# MINI58DE_v1 register map
File version: 1.0
Registers are 32-bit, read-write, reset 0x0 unless marked. A register's access mark holds for its fields unless they carry their own. Offsets are from the block's base; [hi:lo] are bit positions; {n}, {i} and the like mark numbered series.

## INT — INT Register Map
Base 0x50000300
0x00 IRQ0_SRC ro reset not defined — IRQ0 (BOD) Interrupt Source Identity
  [0] BOD_INT — IRQ0 Source Identity
    0=IRQ0 source is not from BOD interrupt (BOD_INT); 1=IRQ0 source is from BOD interrupt (BOD_INT)
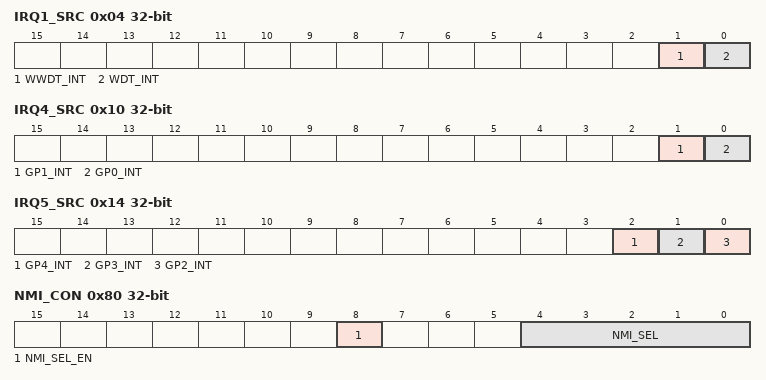
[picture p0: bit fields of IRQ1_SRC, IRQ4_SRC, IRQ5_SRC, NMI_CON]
0x04 IRQ1_SRC ro reset not defined — IRQ1 (WDT) Interrupt Source Identity
  [1] WWDT_INT — IRQ1 Source Identity
    0=IRQ1 source is not from window watchdog interrupt (WWDT _INT); 1=IRQ1 source is from window watchdog interrupt (WWDT_INT)
  [0] WDT_INT — IRQ1 Source Identity
    0=IRQ1 source is not from watchdog interrupt (WDT _INT); 1=IRQ1 source is from watchdog interrupt (WDT_INT)
0x08 IRQ2_SRC ro reset not defined — IRQ2 (EINT0) Interrupt Source Identity
  [0] EINT0 — IRQ2 Source Identity
    0=IRQ2 source is not from external signal interrupt 0 from P3.2 (EINT0); 1=IRQ2 source is from external signal interrupt 0 from P3.2 (EINT0)
0x0C IRQ3_SRC ro reset not defined — IRQ3 (EINT1) Interrupt Source Identity
  [0] EINT1 — IRQ3 Source Identity
    0=IRQ3 source is not from external signal interrupt 1 from P5.2 (EINT1); 1=IRQ3 source is from external signal interrupt 1 from P5.2 (EINT1)
0x10 IRQ4_SRC ro reset not defined — IRQ4 (GP0/1) Interrupt Source Identity
  [1] GP1_INT — IRQ4 Source Identity
    0=IRQ4 source is not from GP1 interrupt (GP1_INT); 1=IRQ4 source is from GP1 interrupt (GP1_INT)
  [0] GP0_INT — IRQ4 Source Identity
    0=IRQ4 source is not from GP0 interrupt (GP0_INT); 1=IRQ4 source is from GP0 interrupt (GP0_INT)
0x14 IRQ5_SRC ro reset not defined — IRQ5 (GP2/3/4) Interrupt Source Identity
  [2] GP4_INT — IRQ5 Source Identity
    0=IRQ5 source is not from GP4 interrupt (GP4_INT); 1=IRQ5 source is from GP4 interrupt (GP4_INT)
  [1] GP3_INT — IRQ5 Source Identity
    0=IRQ5 source is not from GP3 interrupt (GP3_INT); 1=IRQ5 source is from GP3 interrupt (GP3_INT)
  [0] GP2_INT — IRQ5 Source Identity
    0=IRQ5 source is not from GP2 interrupt (GP2_INT); 1=IRQ5 source is from GP2 interrupt (GP2_INT)
0x18 IRQ6_SRC ro reset not defined — IRQ6 (PWM) Interrupt Source Identity
  [0] PWM_INT — IRQ6 Source Identity
    0=IRQ6 source is not from PWM interrupt (PWM_INT); 1=IRQ6 source is from PWM interrupt (PWM_INT)
0x1C IRQ7_SRC ro reset not defined — IRQ7 (BRAKE) Interrupt Source Identity
  [0] BRAKE_INT — IRQ7 Source Identity
    0=IRQ7 source is not from Brake interrupt (BRAKE_INT); 1=IRQ7 source is from Brake interrupt (BRAKE_INT)
0x20 IRQ8_SRC ro reset not defined — IRQ8 (TMR0) Interrupt Source Identity
  [0] TMR0_INT — IRQ8 Source Identity
    0=IRQ8 source is not from Timer0 interrupt (TMR0_INT); 1=IRQ8 source is from Timer0 interrupt (TMR0_INT)
0x24 IRQ9_SRC ro reset not defined — IRQ9 (TMR1) Interrupt Source Identity
  [0] TMR1_INT — IRQ9 Source Identity
    0=IRQ9 source is not from Timer1 interrupt (TMR1_INT); 1=IRQ9 source is from Timer1 interrupt (TMR1_INT)
0x28 IRQ10_SRC reset not defined — Reserved
0x2C IRQ11_SRC reset not defined — Reserved
0x30 IRQ12_SRC ro reset not defined — IRQ12 (UART0) Interrupt Source Identity
  [0] UART0_INT — IRQ12 Source Identity
    0=IRQ12 source is not from UART0 interrupt (UART0_INT); 1=IRQ12 source is from UART0 interrupt (UART0_INT)
0x34 IRQ13_SRC ro reset not defined — IRQ13 (UART1) Interrupt Source Identity
  [0] UART1_INT — IRQ13 Source Identity
    0=IRQ13 source is not from UART1 interrupt (UART1_INT); 1=IRQ13 source is from UART1 interrupt (UART1_INT)
0x38 IRQ14_SRC ro reset not defined — IRQ14 (SPI) Interrupt Source Identity
  [0] SPI_INT — IRQ14 Source Identity
    0=IRQ14 source is not from SPI interrupt (SPI_INT); 1=IRQ14 source is from SPI interrupt (SPI_INT)
0x3C IRQ15_SRC reset not defined — Reserved
0x40 IRQ16_SRC ro reset not defined — IRQ16 (GP5) Interrupt Source Identity
  [0] GP5_INT — IRQ16 Source Identity
    0=IRQ16 source is not from GP5 interrupt (GP5_INT); 1=IRQ16 source is from GP5 interrupt (GP5_INT)
0x44 IRQ17_SRC ro reset not defined — IRQ17 (HIRC Trim) Interrupt Source Identity
  [0] HIRC_TRIM_INT — IRQ17 Source Identity
    0=IRQ17 source is not from HIRC trim interrupt (HIRC_TRIM_INT); 1=IRQ17 source is from HIRC trim interrupt (HIRC_TRIM_INT)
0x48 IRQ18_SRC ro reset not defined — IRQ18 (I2C0) Interrupt Source Identity
  [0] I2C0_INT — IRQ18 Source Identity
    0=IRQ18 source is not from I2C0 interrupt (I2C0_INT); 1=IRQ18 source is from I2C0 interrupt (I2C0_INT)
0x4C IRQ19_SRC ro reset not defined — IRQ19 (I2C1) Interrupt Source Identity
  [0] I2C1_INT — IRQ19 Source Identity
    0=IRQ19 source is not from I2C1 interrupt (I2C1_INT); 1=IRQ19 source is from I2C1 interrupt (I2C1_INT)
{0x0+4i} IRQ{i}_SRC reset not defined (i=20..24) — Reserved
0x64 IRQ25_SRC ro reset not defined — IRQ25 (ACMP) Interrupt Source Identity
  [0] ACMP_INT — IRQ25 Source Identity
    0=IRQ25 source is not from ACMP interrupt (ACMP_INT); 1=IRQ25 source is from ACMP interrupt (ACMP_INT)
0x68 IRQ26_SRC reset not defined — Reserved
0x6C IRQ27_SRC reset not defined — Reserved
0x70 IRQ28_SRC ro reset not defined — IRQ28 (PWRWU) Interrupt Source Identity
  [0] PWRWU_INT — IRQ28 Source Identity
    0=IRQ28 source is not from PWRWU interrupt (PWRWU_INT); 1=IRQ28 source is from PWREU interrupt (PWRWU_INT)
0x74 IRQ29_SRC ro reset not defined — IRQ29 (ADC) Interrupt Source Identity
  [0] ADC_INT — IRQ29 Source Identity
    0=IRQ29 source is not from ADC interrupt (ADC_INT); 1=IRQ29 source is from ADC interrupt (ADC_INT)
0x78 IRQ30_SRC reset not defined — Reserved
0x7C IRQ31_SRC reset not defined — Reserved
0x80 NMI_CON — NMI Source Interrupt Select Control Register
  [8] NMI_SEL_EN — NMI Interrupt Enable Bit (Write Protected). Note: This bit is the protected bit, and programming it needs to write 0x59, 0x16, and 0x88 to address 0x5000_0100 to disable register protection. Refer to the register SYS_REGLCTL at address SYS_BA+0x100.
    0=NMI interrupt Disabled; 1=NMI interrupt Enabled
  [4:0] NMI_SEL — NMI Interrupt Source Select Bit. The NMI interrupt to Cortex-M0 can be selected from one of the peripheral interrupt by setting NMI_SEL.
0x84 MCU_IRQ — MCU IRQ Number Identity Register
  [31:0] MCU_IRQ — MCU IRQ Source Bits. The MCU_IRQ collects all the interrupts from the peripherals and generates the synchronous interrupt to Cortex-M0 core. There are two modes to generate interrupt to Cortex-M0 - the normal mode and test mode. The MCU_IRQ collects all interrupts from each peripheral and synchronizes them then interrupts the Cortex-M0. When the MCU_IRQ[n] is 0, setting MCU_IRQ[n] to 1 will generate an interrupt to Cortex-M0 NVIC[n]. When the MCU_IRQ[n] is 1 (mean an interrupt is assert), setting 1 to the MCU_bit[n] will clear the interrupt and setting MCU_IRQ[n] 0 has no effect.
